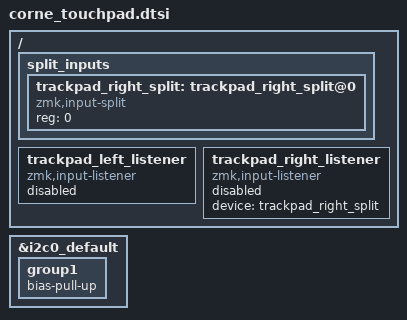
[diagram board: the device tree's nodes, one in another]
/*
 * Éléments partagés par les deux moitiés : le pad droit (périphérique) est
 * relayé vers la moitié gauche (centrale) via un zmk,input-split.
 */

/*
 * Pull-ups internes sur SDA/SCL : ce sont normalement ceux du module OLED
 * qui polarisent le bus. Sans OLED (ou si le TPS43 n'en a pas), l'I2C reste
 * muet. Les pull-ups internes (~13 kΩ) suffisent pour des fils courts.
 */
&i2c0_default {
    group1 {
        bias-pull-up;
    };
};

/ {
    split_inputs {
        #address-cells = <1>;
        #size-cells = <0>;

        trackpad_right_split: trackpad_right_split@0 {
            compatible = "zmk,input-split";
            reg = <0>;
        };  
    };

    trackpad_left_listener: trackpad_left_listener {
        compatible = "zmk,input-listener";
        status = "disabled";
    };

    trackpad_right_listener: trackpad_right_listener {
        compatible = "zmk,input-listener";
        status = "disabled";
        device = <&trackpad_right_split>;
    };
};
